# ESP32-H4 register map
Vendor: ESPRESSIF SYSTEMS (SHANGHAI) CO., LTD.; Series: ESP32 H-Series; File version: 1
CPU: RV32IMAC r0p0, little endian, no MPU, no FPU, 0 interrupt priority bits
Address unit: 32 bits
Registers are 32-bit, read-write, reset 0x0 unless marked. A register's access mark holds for its fields unless they carry their own. Offsets are from the block's base; [hi:lo] are bit positions; {n}, {i} and the like mark numbered series.

## RMT — Remote Control
Base 0x6001E000
{0x0+4i} CH{i}DATA (i=0..3) ro — The read and write data register for channel {i} by APB FIFO access.
  [31:0] CHDATA — Read and write data for channel %s via APB FIFO.
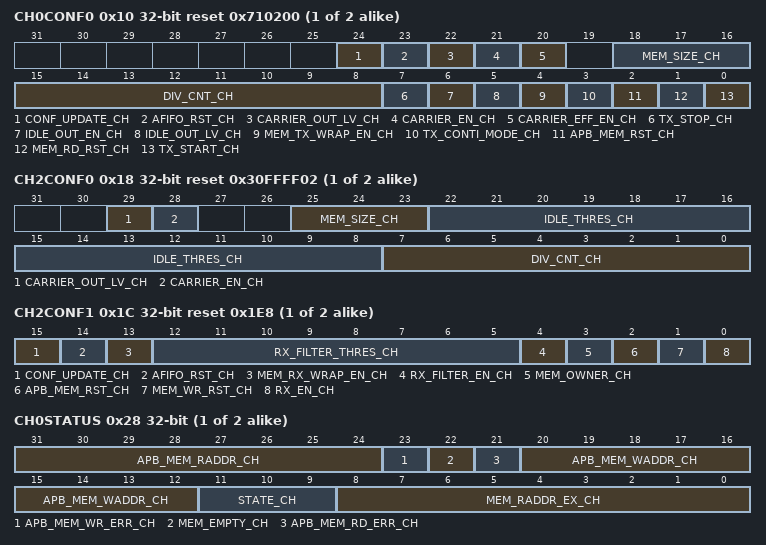
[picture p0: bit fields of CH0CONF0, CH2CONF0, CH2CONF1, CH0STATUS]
{0x10+4i} CH{i}CONF0 (i=0..1) access per field reset 0x710200 — Configuration register 0 for channel {i}
  [24] CONF_UPDATE_CH wo — Synchronization bit for channel %s.
  [23] AFIFO_RST_CH wo — Reserved
  [22] CARRIER_OUT_LV_CH rw — Configures the position of carrier wave for channel %s. \\ 0: Add carrier wave on low level\\ 1: Add carrier wave on high level\\
  [21] CARRIER_EN_CH rw — Configures whether to enable the carrier modulation on output signal for channel %s. \\ 0: Disable\\ 1: Enable\\
  [20] CARRIER_EFF_EN_CH rw — Configures whether to add carrier modulation on the output signal only at data-sending state for channel %s. \\ 0: Add carrier modulation on the output signal at data-sending state and idle state for channel %s\\ 1: Add carrier modulation on the output signal only at data-sending state for channel %s\\ Only valid when RMT_CARRIER_EN_CH%s is 1.\\
  [18:16] MEM_SIZE_CH rw — Configures the maximum number of memory blocks allocated to channel %s.
  [15:8] DIV_CNT_CH rw — Configures the divider for clock of channel %s. \\ Measurement unit: rmt_sclk\\
  [7] TX_STOP_CH rw — Configures whether to stop the transmitter of channel %s sending data out. \\ 0: No effect\\ 1: Stop\\
  [6] IDLE_OUT_EN_CH rw — Configures whether to enable the output for channel %s in idle state. \\ 0: No effect\\ 1: Enable\\
  [5] IDLE_OUT_LV_CH rw — Configures the level of output signal for channel %s when the transmitter is in idle state.
  [4] MEM_TX_WRAP_EN_CH rw — Configures whether to enable wrap TX mode for channel %s. \\ 0: No effect\\ 1: Enable\\ In this mode, if the TX data size is larger than the channel's RAM block size, the transmitter continues transmitting the first data to the last data in loops.\\
  [3] TX_CONTI_MODE_CH rw — Configures whether to enable continuous TX mode for channel %s. \\ 0: No Effect\\ 1: Enable\\ In this mode, the transmitter starts transmission from the first data. If an end-marker is encountered, the transmitter starts transmitting data from the first data again. if no end-marker is encountered, the transmitter starts transmitting the first data again when the last data is transmitted.\\
  [2] APB_MEM_RST_CH wo — Configures whether to reset RAM W/R address accessed by APB FIFO for channel %s. \\ 0: No effect\\ 1: Reset\\
  [1] MEM_RD_RST_CH wo — Configures whether to reset RAM read address accessed by the transmitter for channel %s. \\ 0: No effect\\ 1: Reset\\
  [0] TX_START_CH wo — Configures whether to enable sending data in channel %s. \\ 0: No effect\\ 1: Enable\\
{0x8+8i} CH{i}CONF0 (i=2..3) reset 0x30FFFF02 — Configuration register 0 for channel {i}
  [29] CARRIER_OUT_LV_CH — Configures the position of carrier wave for channel %s. \\ 0: Add carrier wave on low level\\ 1: Add carrier wave on high level\\
  [28] CARRIER_EN_CH — Configures whether to enable carrier modulation on output signal for channel %s. \\ 0: Disable\\ 1: Enable\\
  [25:23] MEM_SIZE_CH — Configures the maximum number of memory blocks allocated to channel %s.
  [22:8] IDLE_THRES_CH — Configures RX threshold. \\ When no edge is detected on the input signal for continuous clock cycles longer than this field value, the receiver stops receiving data.\\ Measurement unit: clk_div\\
  [7:0] DIV_CNT_CH — Configures the clock divider of channel %s. \\ Measurement unit: rmt_sclk\\
{0xC+8i} CH{i}CONF1 (i=2..3) access per field reset 0x1E8 — Configuration register 1 for channel {i}
  [15] CONF_UPDATE_CH wo — Synchronization bit for channel %s.
  [14] AFIFO_RST_CH wo — Reserved
  [13] MEM_RX_WRAP_EN_CH rw — Configures whether to enable wrap RX mode for channel %s. \\ 0: Disable\\ 1: Enable\\ In this mode, if the RX data size is larger than channel %s's RAM block size, the receiver stores the RX data from the first address to the last address in loops.\\
  [12:5] RX_FILTER_THRES_CH rw — Configures whether the receiver, when receiving data, ignores the input pulse when its width is shorter than this register value in units of rmt_sclk cycles. \\ 0: No effect\\ 1: Reset\\
  [4] RX_FILTER_EN_CH rw — Configures whether to enable the receiver's filter for channel %s. \\ 0: Disable\\ 1: Enable\\
  [3] MEM_OWNER_CH rw — Configures the ownership of channel %s's RAM block. \\ 0: APB bus is using the RAM\\ 1: Receiver is using the RAM\\
  [2] APB_MEM_RST_CH wo — Configures whether to reset RAM W/R address accessed by APB FIFO for channel %s. \\ 0: No effect\\ 1: Reset\\
  [1] MEM_WR_RST_CH wo — Configures whether to reset RAM write address accessed by the receiver for channel %s. \\ 0: No effect\\ 1: Reset\\
  [0] RX_EN_CH rw — Configures whether to enable the receiver to start receiving data in channel %s. \\ 0: Disable\\ 1: Enable\\
{0x28+4i} CH{i}STATUS (i=0..1) ro — Channel {i} status register
  [31:24] APB_MEM_RADDR_CH — Represents the memory address offset when reading RAM over APB bus.
  [23] APB_MEM_WR_ERR_CH — Represents whether the offset address exceeds memory size (overflows) when writes via APB bus. \\ 0: Not exceed\\ 1: Exceed\\
  [22] MEM_EMPTY_CH — Represents whether the TX data size exceeds the memory size and the wrap TX mode is disabled. \\ 0: Not exceed\\ 1: Exceed\\
  [21] APB_MEM_RD_ERR_CH — Represents whether the offset address exceeds memory size when reading via APB bus. \\ 0: Not exceed\\ 1: Exceed\\
  [20:12] APB_MEM_WADDR_CH — Represents the memory address offset when writes RAM over APB bus.
  [11:9] STATE_CH — Represents the FSM status of channel %s.
  [8:0] MEM_RADDR_EX_CH — Represents the memory address offset when transmitter of channel %s is using the RAM.
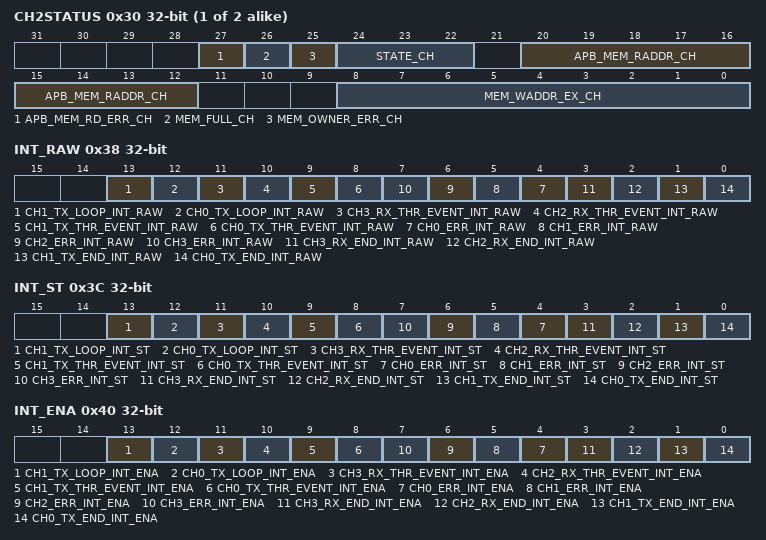
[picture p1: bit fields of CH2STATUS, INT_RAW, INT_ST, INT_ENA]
{0x28+4i} CH{i}STATUS (i=2..3) ro — Channel {i} status register
  [27] APB_MEM_RD_ERR_CH — Represents whether the offset address exceeds memory size (overflows) when reads RAM via APB bus. \\ 0: Not exceed\\ 1: Exceed\\
  [26] MEM_FULL_CH — Represents whether the receiver receives more data than the memory can fit. \\ 0: The receiver does not receive more data than the memory can fit\\ 1: The receiver receives more data than the memory can fit\\
  [25] MEM_OWNER_ERR_CH — Represents whether the ownership of memory block is wrong. \\ 0: The ownership of memory block is correct\\ 1: The ownership of memory block is wrong\\
  [24:22] STATE_CH — Represents the FSM status of channel %s.
  [20:12] APB_MEM_RADDR_CH — Represents the memory address offset when reads RAM over APB bus.
  [8:0] MEM_WADDR_EX_CH — Represents the memory address offset when receiver of channel %s is using the RAM.
0x38 INT_RAW — Raw interrupt status
  [13] CH1_TX_LOOP_INT_RAW — The interrupt raw bit for CHANNEL1. Triggered when the loop count reaches the configured threshold value.
  [12] CH0_TX_LOOP_INT_RAW — The interrupt raw bit for CHANNEL0. Triggered when the loop count reaches the configured threshold value.
  [11] CH3_RX_THR_EVENT_INT_RAW — The interrupt raw bit for CHANNEL3. Triggered when receiver receive more data than configured value.
  [10] CH2_RX_THR_EVENT_INT_RAW — The interrupt raw bit for CHANNEL2. Triggered when receiver receive more data than configured value.
  [9] CH1_TX_THR_EVENT_INT_RAW — The interrupt raw bit for CHANNEL1. Triggered when transmitter sent more data than configured value.
  [8] CH0_TX_THR_EVENT_INT_RAW — The interrupt raw bit for CHANNEL0. Triggered when transmitter sent more data than configured value.
  [n+4] CH{n}_ERR_INT_RAW (n=0..3) — The interrupt raw bit for CHANNEL{n+4}. Triggered when error occurs.
  [3] CH3_RX_END_INT_RAW — The interrupt raw bit for CHANNEL3. Triggered when reception done.
  [2] CH2_RX_END_INT_RAW — The interrupt raw bit for CHANNEL2. Triggered when reception done.
  [1] CH1_TX_END_INT_RAW — The interrupt raw bit for CHANNEL1. Triggered when transmission done.
  [0] CH0_TX_END_INT_RAW — The interrupt raw bit for CHANNEL0. Triggered when transmission done.
0x3C INT_ST ro — Masked interrupt status
  [13] CH1_TX_LOOP_INT_ST — The masked interrupt status bit for CH1_TX_LOOP_INT.
  [12] CH0_TX_LOOP_INT_ST — The masked interrupt status bit for CH0_TX_LOOP_INT.
  [11] CH3_RX_THR_EVENT_INT_ST — The masked interrupt status bit for CH3_RX_THR_EVENT_INT.
  [10] CH2_RX_THR_EVENT_INT_ST — The masked interrupt status bit for CH2_RX_THR_EVENT_INT.
  [9] CH1_TX_THR_EVENT_INT_ST — The masked interrupt status bit for CH1_TX_THR_EVENT_INT.
  [8] CH0_TX_THR_EVENT_INT_ST — The masked interrupt status bit for CH0_TX_THR_EVENT_INT.
  [n+4] CH{n}_ERR_INT_ST (n=0..3) — The masked interrupt status bit for CH{n+4}_ERR_INT.
  [3] CH3_RX_END_INT_ST — The masked interrupt status bit for CH3_RX_END_INT.
  [2] CH2_RX_END_INT_ST — The masked interrupt status bit for CH2_RX_END_INT.
  [1] CH1_TX_END_INT_ST — The masked interrupt status bit for CH1_TX_END_INT.
  [0] CH0_TX_END_INT_ST — The masked interrupt status bit for CH0_TX_END_INT.
0x40 INT_ENA — Interrupt enable bits
  [13] CH1_TX_LOOP_INT_ENA — The interrupt enable bit for CH1_TX_LOOP_INT.
  [12] CH0_TX_LOOP_INT_ENA — The interrupt enable bit for CH0_TX_LOOP_INT.
  [11] CH3_RX_THR_EVENT_INT_ENA — The interrupt enable bit for CH3_RX_THR_EVENT_INT.
  [10] CH2_RX_THR_EVENT_INT_ENA — The interrupt enable bit for CH2_RX_THR_EVENT_INT.
  [9] CH1_TX_THR_EVENT_INT_ENA — The interrupt enable bit for CH1_TX_THR_EVENT_INT.
  [8] CH0_TX_THR_EVENT_INT_ENA — The interrupt enable bit for CH0_TX_THR_EVENT_INT.
  [n+4] CH{n}_ERR_INT_ENA (n=0..3) — The interrupt enable bit for CH{n+4}_ERR_INT.
  [3] CH3_RX_END_INT_ENA — The interrupt enable bit for CH3_RX_END_INT.
  [2] CH2_RX_END_INT_ENA — The interrupt enable bit for CH2_RX_END_INT.
  [1] CH1_TX_END_INT_ENA — The interrupt enable bit for CH1_TX_END_INT.
  [0] CH0_TX_END_INT_ENA — The interrupt enable bit for CH0_TX_END_INT.
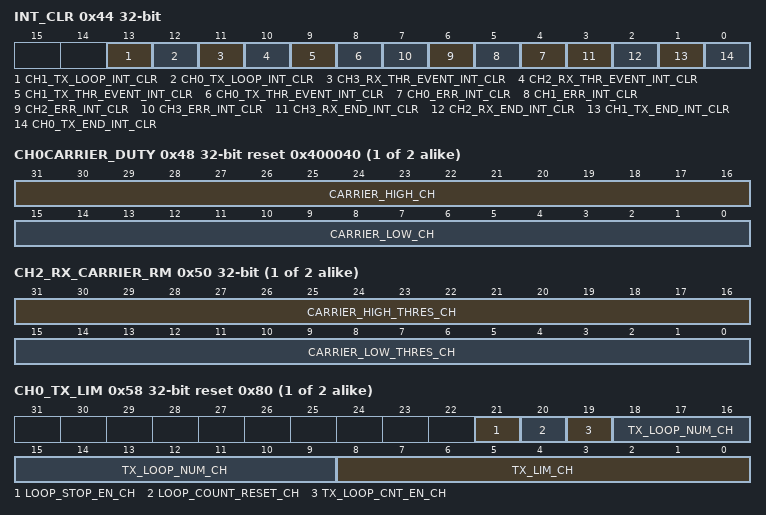
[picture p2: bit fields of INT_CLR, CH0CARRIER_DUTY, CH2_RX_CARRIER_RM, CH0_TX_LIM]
0x44 INT_CLR wo — Interrupt clear bits
  [13] CH1_TX_LOOP_INT_CLR — Set this bit to clear theCH1_TX_LOOP_INT interrupt.
  [12] CH0_TX_LOOP_INT_CLR — Set this bit to clear theCH0_TX_LOOP_INT interrupt.
  [11] CH3_RX_THR_EVENT_INT_CLR — Set this bit to clear theCH3_RX_THR_EVENT_INT interrupt.
  [10] CH2_RX_THR_EVENT_INT_CLR — Set this bit to clear theCH2_RX_THR_EVENT_INT interrupt.
  [9] CH1_TX_THR_EVENT_INT_CLR — Set this bit to clear theCH1_TX_THR_EVENT_INT interrupt.
  [8] CH0_TX_THR_EVENT_INT_CLR — Set this bit to clear theCH0_TX_THR_EVENT_INT interrupt.
  [n+4] CH{n}_ERR_INT_CLR (n=0..3) — Set this bit to clear theCH{n+4}_ERR_INT interrupt.
  [3] CH3_RX_END_INT_CLR — Set this bit to clear theCH3_RX_END_INT interrupt.
  [2] CH2_RX_END_INT_CLR — Set this bit to clear theCH2_RX_END_INT interrupt.
  [1] CH1_TX_END_INT_CLR — Set this bit to clear theCH1_TX_END_INT interrupt.
  [0] CH0_TX_END_INT_CLR — Set this bit to clear theCH0_TX_END_INT interrupt.
{0x48+4i} CH{i}CARRIER_DUTY (i=0..1) reset 0x400040 — Duty cycle configuration register for channel {i}
  [31:16] CARRIER_HIGH_CH — Configures carrier wave's high level clock period for channel %s. \\ Measurement unit: rmt_sclk\\
  [15:0] CARRIER_LOW_CH — Configures carrier wave's low level clock period for channel %s. \\ Measurement unit: rmt_sclk\\
{0x48+4i} CH{i}_RX_CARRIER_RM (i=2..3) — Carrier remove register for channel {i}
  [31:16] CARRIER_HIGH_THRES_CH — Configures the high level period in a carrier modulation mode for channel %s. \\ The high level period in a carrier modulation mode is (REG_RMT_REG_CARRIER_HIGH_THRES_CH%s + 1) for channel %s.\\ Measurement unit: clk_div\\
  [15:0] CARRIER_LOW_THRES_CH — Configures the low level period in a carrier modulation mode for channel %s. \\ The low level period in a carrier modulation mode is (RMT_CARRIER_LOW_THRES_CH%s + 1) for channel %s. \\ Measurement unit: clk_div\\
{0x58+4i} CH{i}_TX_LIM (i=0..1) access per field reset 0x80 — Configuration register for channel {i} TX event
  [21] LOOP_STOP_EN_CH rw — Configures whether to enable the loop send stop function after the loop counter counts to loop number for channel %s. \\ 0: No effect\\ 1: Enable\\
  [20] LOOP_COUNT_RESET_CH wo — Configures whether to reset the loop count when tx_conti_mode is valid. \\ 0: No effect\\ 1: Reset\\
  [19] TX_LOOP_CNT_EN_CH rw — Configures whether to enable loop count. \\ 0: No effect\\ 1: Enable\\
  [18:9] TX_LOOP_NUM_CH rw — Configures the maximum loop count when Continuous TX mode is valid.
  [8:0] TX_LIM_CH rw — Configures the maximum entries that channel %s can send out.
{0x58+4i} CH{i}_RX_LIM (i=2..3) reset 0x80 — Configuration register for channel {i} RX event
  [8:0] RX_LIM_CH — This register is used to configure the maximum entries that CHANNEL%s can receive.
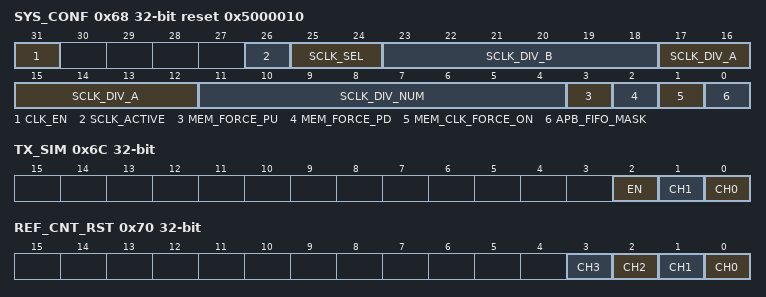
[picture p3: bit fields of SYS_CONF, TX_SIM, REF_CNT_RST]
0x68 SYS_CONF reset 0x5000010 — Configuration register for RMT APB
  [31] CLK_EN — Configures whether to enable signal of RMT register clock gate. \\ 0: Power down the drive clock of registers\\ 1: Power up the drive clock of registers\\
  [26] SCLK_ACTIVE — rmt_sclk switch
  [25:24] SCLK_SEL — choose the clock source of rmt_sclk. 1:CLK_80Mhz,2:CLK_FOSC, 3:XTAL
  [23:18] SCLK_DIV_B — the denominator of the fractional part of the fractional divisor
  [17:12] SCLK_DIV_A — the numerator of the fractional part of the fractional divisor
  [11:4] SCLK_DIV_NUM — the integral part of the fractional divisor
  [3] MEM_FORCE_PU — 1: Disable RMT memory light sleep power down function. 0: Power down RMT memory when RMT is in light sleep mode.
  [2] MEM_FORCE_PD — Set this bit to power down RMT memory.
  [1] MEM_CLK_FORCE_ON — Configures whether to enable the clock for RMT memory. \\ 0: Disable\\ 1: Enable\\
  [0] APB_FIFO_MASK — Configures the memory access mode. \\ 0: Access memory by FIFO\\ 1: Access memory directly\\
0x6C TX_SIM — RMT TX synchronous register
  [2] EN — This register is used to enable multiple of channels to start sending data synchronously.
  [1] CH1 — Set this bit to enable CHANNEL1 to start sending data synchronously with other enabled channels.
  [0] CH0 — Set this bit to enable CHANNEL0 to start sending data synchronously with other enabled channels.
0x70 REF_CNT_RST wo — RMT clock divider reset register
  [n] CH{n} (n=0..3) — This register is used to reset the clock divider of CHANNEL{n}.
0xCC DATE reset 0x2108213 — Version control register
  [27:0] DATE — This is the version register.
